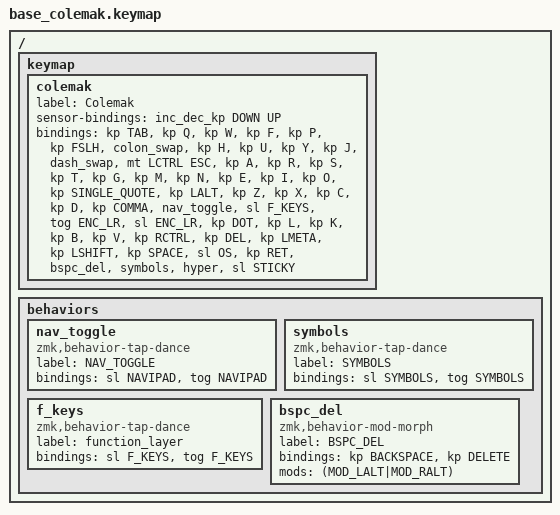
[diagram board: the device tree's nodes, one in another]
/ {
    keymap {
        colemak {
            label = "Colemak";
            sensor-bindings = <&inc_dec_kp DOWN UP>;
            bindings = <
//    ┌───────────┬────┬────┬──────┬───────┬─────────┐                                                  ┌─────────┬──────┬───────────┬────┬────┬───────┐
//    │    TAB    │  Q │  W │   F  │   P   │    /    │                                                  │   : ;   │   H  │     U     │  Y │  J │  _ -  │
//    ├───────────┼────┼────┼──────┼───────┼─────────┤                                                  ├─────────┼──────┼───────────┼────┼────┼───────┤
//    │  CTRL ESC │  A │  R │   S  │   T   │    G    │                                                  │    M    │   N  │     E     │  I │  O │  ' "  │
//    ├───────────┼────┼────┼──────┼───────┼─────────┼─────────┬───────────┐   ┌────────────┬───────────┼─────────┼──────┼───────────┼────┼────┼───────┤
//    │    ALT    │  Z │  X │   C  │   D   │    ,    │ navipad │ sl F_KEYS │   │ tog ENC_LR │ sl ENC_LR │    .    │   L  │     K     │  B │  V │  CTRL │
//    └───────────┴────┴────┼──────┼───────┼─────────┼─────────┼───────────┤   ├────────────┼───────────┼─────────┼──────┼───────────┼────┴────┴───────┘
//                          │  DEL │  META │  LSHIFT │  SPACE  │   sl OS   │   │    enter   │ bspc/del  │ symbols │ hype │ sl STICKY │                  
//                          └──────┴───────┴─────────┴─────────┴───────────┘   └────────────┴───────────┴─────────┴──────┴───────────┘                  
  &kp TAB         &kp Q   &kp W   &kp F     &kp P       &kp FSLH                                                               &colon_swap   &kp H    &kp U        &kp Y   &kp J   &dash_swap      
  &mt LCTRL ESC   &kp A   &kp R   &kp S     &kp T       &kp G                                                                  &kp M         &kp N    &kp E        &kp I   &kp O   &kp SINGLE_QUOTE
  &kp LALT        &kp Z   &kp X   &kp C     &kp D       &kp COMMA    &nav_toggle   &sl F_KEYS       &tog ENC_LR   &sl ENC_LR   &kp DOT       &kp L    &kp K        &kp B   &kp V   &kp RCTRL       
                                  &kp DEL   &kp LMETA   &kp LSHIFT   &kp SPACE     &sl OS           &kp RET       &bspc_del    &symbols      &hyper   &sl STICKY                                   
            >;
        };
	};
    behaviors {
        nav_toggle: nav_toggle {
            // tap - sticky / hold - momentary / double tap - toggle
			compatible = "zmk,behavior-tap-dance";
			label = "NAV_TOGGLE";
			#binding-cells = <0>;
			bindings = <&sl NAVIPAD>, <&tog NAVIPAD>;
		};
        symbols: symbols {
            compatible = "zmk,behavior-tap-dance";
            label = "SYMBOLS";
            #binding-cells = <0>;
            bindings = <&sl SYMBOLS>, <&tog SYMBOLS>;
        };
        f_keys: f_keys {
			compatible = "zmk,behavior-tap-dance";
			label = "function_layer";
			#binding-cells = <0>;
			bindings = <&sl F_KEYS>, <&tog F_KEYS>;
		};
        bspc_del: bspc_del {
			compatible = "zmk,behavior-mod-morph";
			label = "BSPC_DEL";
			bindings =
				<&kp BACKSPACE>,
				<&kp DELETE>;
			#binding-cells = <0>;
			mods = <(MOD_LALT|MOD_RALT)>;
		};
    };
};
